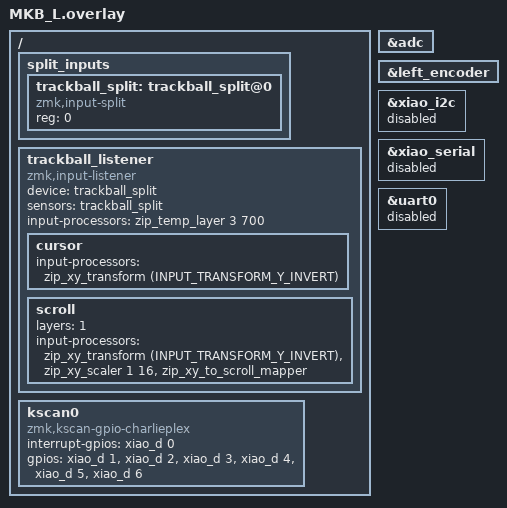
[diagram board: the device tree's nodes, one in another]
#include <dt-bindings/zmk/bt.h>
#include <input/processors.dtsi>
#include <dt-bindings/zmk/input_transform.h>
#include <zephyr/dt-bindings/input/input-event-codes.h>
#include "MKB_pinctrl_L.dtsi"
#include "MKB.dtsi"

&adc {
	status = "okay";
};

/ {
    // anin0: analog_input_0 {
    //     compatible = "zmk,analog-input";
    //     sampling-hz = <100>;
    //     x-ch {
    //         io-channels = <&xiao_d 10>;
    //         mv-mid = <1600>;
    //         mv-min-max = <1600>;
    //         mv-deadzone = <88>;
    //         scale-multiplier = <1>;
    //         scale-divisor = <800>;
    //         invert;
    //         evt-type = <INPUT_EV_REL>;
    //         input-code = <INPUT_REL_X>;
    //     };
    //     y-ch {
    //         io-channels = <&xiao_d 9>;
    //         mv-mid = <1600>;
    //         mv-min-max = <1600>;
    //         mv-deadzone = <88>;
    //         scale-multiplier = <1>;
    //         scale-divisor = <800>;
    //         invert;
    //         evt-type = <INPUT_EV_REL>;
    //         input-code = <INPUT_REL_Y>;
    //     };
    // };
    
    // analog_input_listener {
    //     status = "okay";
    //     compatible = "zmk,input-listener";
    //     device = <&anin0>;
    //     input-processors = <&zip_xy_to_scroll_mapper>;
    // };

    split_inputs {
        #address-cells = <1>;
        #size-cells = <0>;

        trackball_split: trackball_split@0 {
            compatible = "zmk,input-split";
            reg = <0>;
        };
    };

    trackball_listener: trackball_listener {
        compatible = "zmk,input-listener";
        status = "okay";
        device = <&trackball_split>;
        sensors = <&trackball_split>;

        cursor {
            input-processors = <&zip_xy_transform (INPUT_TRANSFORM_Y_INVERT)>;
        };

        scroll {
            layers = <1>;
            input-processors = <&zip_xy_transform (INPUT_TRANSFORM_Y_INVERT)>, 
                             <&zip_xy_scaler 1 16>, 
                             <&zip_xy_to_scroll_mapper>;
        };
    };

    kscan0: kscan0 {
        compatible = "zmk,kscan-gpio-charlieplex";
        interrupt-gpios = <&xiao_d 0 (GPIO_ACTIVE_HIGH)>;
        gpios
            = <&xiao_d  1 (GPIO_ACTIVE_HIGH)>
            , <&xiao_d  2 (GPIO_ACTIVE_HIGH)>
            , <&xiao_d  3 (GPIO_ACTIVE_HIGH)>
            , <&xiao_d  4 (GPIO_ACTIVE_HIGH)>
            , <&xiao_d  5 (GPIO_ACTIVE_HIGH)>
            , <&xiao_d  6 (GPIO_ACTIVE_HIGH)>
            ;
    };
};

&trackball_listener {
    status = "okay";
    input-processors = <&zip_temp_layer 3 700>;

    scroll {
        layers = <1>;
        input-processors = <&zip_xy_transform (INPUT_TRANSFORM_Y_INVERT)>, <&zip_xy_scaler 1 16>, <&zip_xy_to_scroll_mapper>;
    };
};

&left_encoder {
    status = "okay";
};

&xiao_i2c { status = "disabled"; };
&xiao_serial { status = "disabled"; };
&uart0 { status = "disabled";};
